# APM32F091 register map
File version: 1.0
Registers are 32-bit, read-write, reset 0x0 unless marked. A register's access mark holds for its fields unless they carry their own. Offsets are from the block's base; [hi:lo] are bit positions; {n}, {i} and the like mark numbered series; 'fields as' and 'values as' point back to an identical list.

## IWDT — Independent watchdog
Base 0x40003000
0x00 KEY wo
  [15:0] KEY — Key value
0x04 PSC — Prescaler register
  [2:0] PSC — Prescaler divider
0x08 CNTRLD reset 0xFFF — Counter reload register
  [11:0] CNTRLD — Watchdog counter reload value
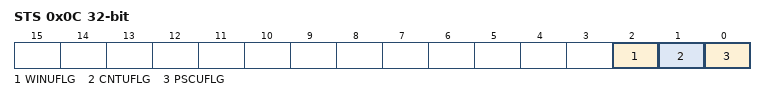
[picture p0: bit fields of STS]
0x0C STS ro — Status register
  [2] WINUFLG — Watchdog counter window value update
  [1] CNTUFLG — Watchdog counter reload value update
  [0] PSCUFLG — Watchdog prescaler value update
0x10 WIN reset 0xFFF — Window register
  [11:0] WIN — Watchdog counter window value

## WWDT — Window watchdog
Base 0x40002C00
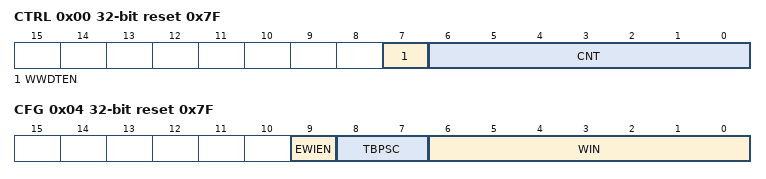
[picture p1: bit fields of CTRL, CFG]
0x00 CTRL reset 0x7F — Control register
  [7] WWDTEN — Activation bit
  [6:0] CNT — 7-bit counter
0x04 CFG reset 0x7F — Configuration register
  [9] EWIEN — Early wakeup interrupt
  [8:7] TBPSC — Timer base
  [6:0] WIN — 7-bit window value
0x08 STS — Status register
  [0] EWIFLG — Early wakeup interrupt flag

## EINT — External interrupt/event controller
Base 0x40010400
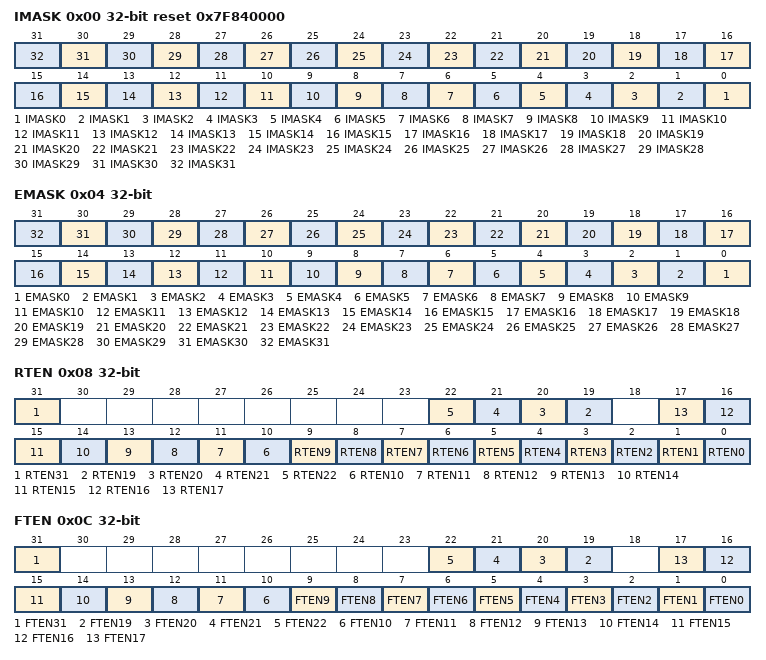
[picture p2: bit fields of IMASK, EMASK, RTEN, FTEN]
0x00 IMASK reset 0x7F840000 — Interrupt mask register
  [n] IMASK{n} (n=0..31) — Interrupt Mask on line {n}
0x04 EMASK — Event mask register
  [n] EMASK{n} (n=0..31) — Event Mask on line {n}
0x08 RTEN — Rising Trigger selection register
  [31] RTEN31 — Rising trigger event configuration of line 31
  [n] RTEN{n} (n=19..22) — Rising trigger event configuration of line {n}
  [n] RTEN{n} (n=0..17) — Rising trigger event configuration of line {n}
0x0C FTEN — Falling Trigger selection register
  [31] FTEN31 — Falling trigger event configuration of line 31
  [n] FTEN{n} (n=19..22) — Falling trigger event configuration of line {n}
  [n] FTEN{n} (n=0..17) — Falling trigger event configuration of line {n}
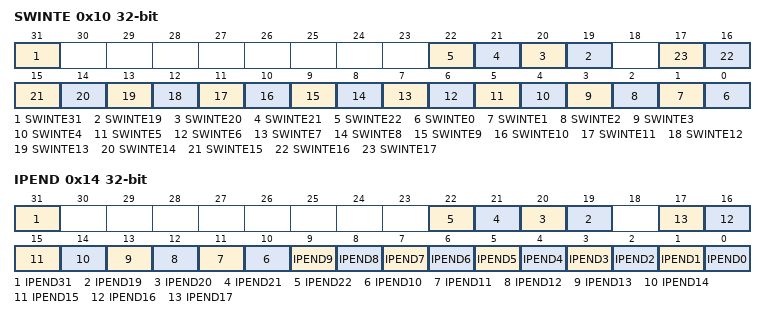
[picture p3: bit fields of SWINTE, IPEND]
0x10 SWINTE — Software interrupt event register
  [31] SWINTE31 — Software Interrupt on line31
  [n] SWINTE{n} (n=19..22) — Software Interrupt on line{n}
  [n] SWINTE{n} (n=0..17) — Software Interrupt on line{n}
0x14 IPEND — Pending register
  [31] IPEND31 — Pending bit 31
  [n] IPEND{n} (n=19..22) — Pending bit {n}
  [n] IPEND{n} (n=0..17) — Pending bit {n}

## DMA1 — DMA1 controller
Base 0x40020000
Same registers: DMA2 0x40020400
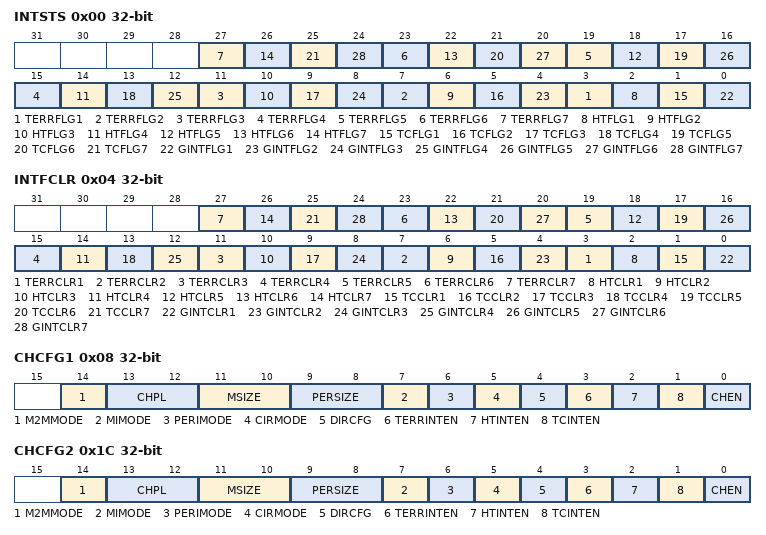
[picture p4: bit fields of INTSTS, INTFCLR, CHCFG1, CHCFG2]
0x00 INTSTS ro — DMA interrupt status register
  [4n-1] TERRFLG{n} (n=1..7) — Channel {n} Transfer Error flag
  [4n-2] HTFLG{n} (n=1..7) — Channel {n} Half Transfer Complete flag
  [4n-3] TCFLG{n} (n=1..7) — Channel {n} Transfer Complete flag
  [4n-4] GINTFLG{n} (n=1..7) — Channel {n} All interrupt flag
0x04 INTFCLR wo — DMA interrupt flag clear register
  [4n-1] TERRCLR{n} (n=1..7) — Channel {n} Transfer Error clear
  [4n-2] HTCLR{n} (n=1..7) — Channel {n} Half Transfer clear
  [4n-3] TCCLR{n} (n=1..7) — Channel {n} Transfer Complete clear
  [4n-4] GINTCLR{n} (n=1..7) — Channel {n} All interrupt clear
0x08 CHCFG1 — DMA channel 1 configuration register
  [14] M2MMODE — Memory to memory mode
  [13:12] CHPL — Channel Priority level
  [11:10] MSIZE — Memory size
  [9:8] PERSIZE — Peripheral size
  [7] MIMODE — Memory increment mode
  [6] PERIMODE — Peripheral increment mode
  [5] CIRMODE — Circular mode
  [4] DIRCFG — Data transfer direction
  [3] TERRINTEN — Transfer error interrupt enable
  [2] HTINTEN — Half Transfer interrupt enable
  [1] TCINTEN — Transfer complete interrupt enable
  [0] CHEN — Channel enable
0x0C CHNDATA1 — DMA channel 1 number of data register
  [15:0] NDATAT — Number of data to transfer
0x10 CHPADDR1 — DMA channel 1 peripheral address register
  [31:0] PERADDR — Peripheral address
{0x0+0x14*i} CHMADDR{i} (i=1..7) — DMA channel {i} memory address register
  [31:0] MEMADDR — Memory address
0x1C CHCFG2 — DMA channel 2 configuration register
  fields as CHCFG1
0x20 CHNDATA2 — DMA channel 2 number of data register
  [15:0] NDATAT — Number of data to transfer
0x24 CHPADDR2 — DMA channel 2 peripheral address register
  [31:0] PERADDR — Peripheral address
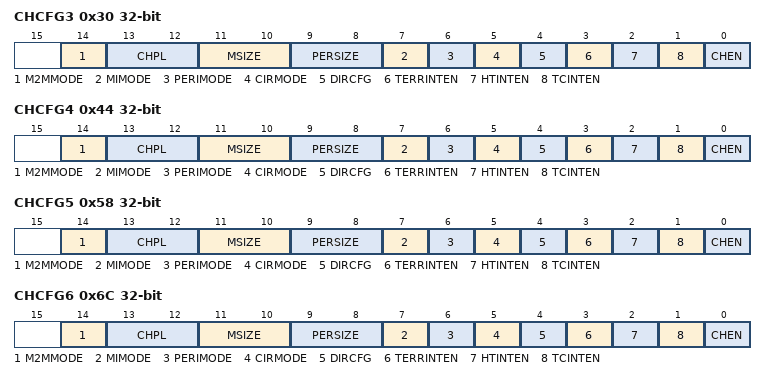
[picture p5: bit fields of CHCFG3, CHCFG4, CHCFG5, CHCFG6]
0x30 CHCFG3 — DMA channel 3 configuration register
  fields as CHCFG1
0x34 CHNDATA3 — DMA channel 3 number of data register
  [15:0] NDATAT — Number of data to transfer
0x38 CHPADDR3 — DMA channel 3 peripheral address register
  [31:0] PERADDR — Peripheral address
0x44 CHCFG4 — DMA channel 4 configuration register
  fields as CHCFG1
0x48 CHNDATA4 — DMA channel 4 number of data register
  [15:0] NDATAT — Number of data to transfer
0x4C CHPADDR4 — DMA channel 4 peripheral address register
  [31:0] PERADDR — Peripheral address
0x58 CHCFG5 — DMA channel 5 configuration register
  fields as CHCFG1
0x5C CHNDATA5 — DMA channel 5 number of data register
  [15:0] NDATAT — Number of data to transfer
0x60 CHPADDR5 — DMA channel 5 peripheral address register
  [31:0] PERADDR — Peripheral address
0x6C CHCFG6 — DMA channel 6 configuration register
  fields as CHCFG1
0x70 CHNDATA6 — DMA channel 6 number of data register
  [15:0] NDATAT — Number of data to transfer
0x74 CHPADDR6 — DMA channel 6 peripheral address register
  [31:0] PERADDR — Peripheral address
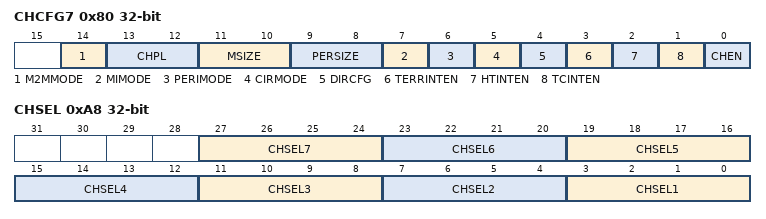
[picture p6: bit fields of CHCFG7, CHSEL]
0x80 CHCFG7 — DMA channel 7 configuration register
  fields as CHCFG1
0x84 CHNDATA7 — DMA channel 7 number of data register
  [15:0] NDATAT — Number of data to transfer
0x88 CHPADDR7 — DMA channel 7 peripheral address register
  [31:0] PERADDR — Peripheral address
0xA8 CHSEL — DMA channel select register
  [4n-1:4n-4] CHSEL{n} (n=1..7) — DMA Channel {n} Select
